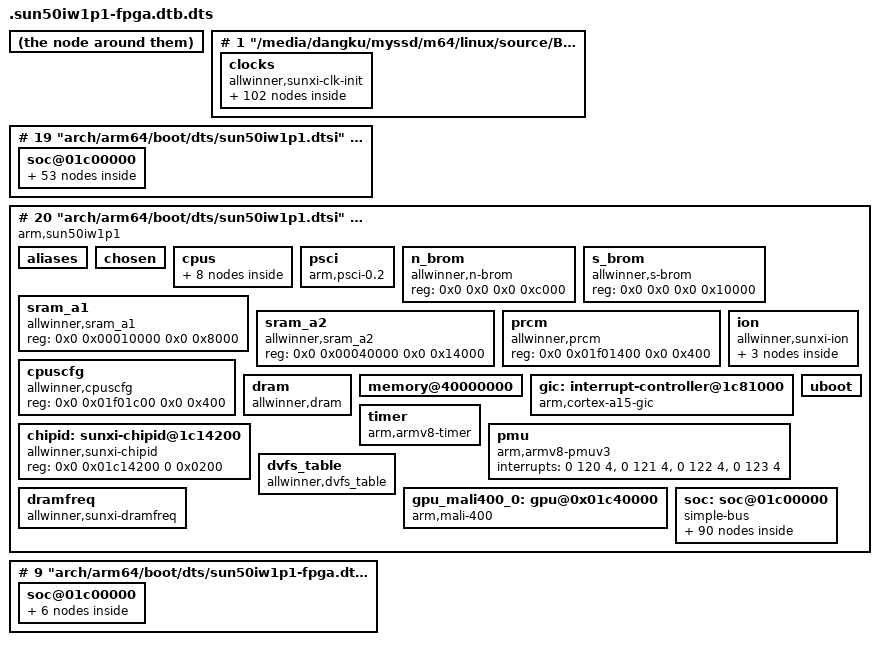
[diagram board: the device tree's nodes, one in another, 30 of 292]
# 1 "arch/arm64/boot/dts/sun50iw1p1-fpga.dts"
# 1 "<built-in>"
# 1 "<command-line>"
# 1 "arch/arm64/boot/dts/sun50iw1p1-fpga.dts"






/dts-v1/;
# 1 "arch/arm64/boot/dts/sun50iw1p1.dtsi" 1







/memreserve/ 0x45000000 0x00200000;
/memreserve/ 0x41010000 0x00010000;
/memreserve/ 0x41020000 0x00000800;

/memreserve/ 0x40100000 0x00004000;
/memreserve/ 0x40104000 0x00001000;
/memreserve/ 0x40105000 0x00001000;

# 1 "/media/dangku/myssd/m64/linux/source/BPI-M64-bsp-open/linux-sunxi/include/dt-bindings/interrupt-controller/arm-gic.h" 1







# 1 "/media/dangku/myssd/m64/linux/source/BPI-M64-bsp-open/linux-sunxi/include/dt-bindings/interrupt-controller/irq.h" 1
# 9 "/media/dangku/myssd/m64/linux/source/BPI-M64-bsp-open/linux-sunxi/include/dt-bindings/interrupt-controller/arm-gic.h" 2
# 17 "arch/arm64/boot/dts/sun50iw1p1.dtsi" 2
# 1 "/media/dangku/myssd/m64/linux/source/BPI-M64-bsp-open/linux-sunxi/include/dt-bindings/gpio/gpio.h" 1
# 18 "arch/arm64/boot/dts/sun50iw1p1.dtsi" 2
# 1 "arch/arm64/boot/dts/sun50iw1p1-clk.dtsi" 1
/{
clocks {
 compatible = "allwinner,sunxi-clk-init";
 device_type = "clocks";
 #address-cells = <2>;
 #size-cells = <2>;
 ranges;
 reg = <0x0 0x01c20000 0x0 0x0320> ,
    <0x0 0x01f01400 0x0 0x00B0> ,
    <0x0 0x01f00060 0x0 0x4>;

  clk_losc: losc {
   #clock-cells = <0>;
   compatible = "allwinner,fixed-clock";
   clock-frequency = <32768>;
   clock-output-names = "losc";
  };

  clk_iosc: iosc {
   #clock-cells = <0>;
   compatible = "allwinner,fixed-clock";
   clock-frequency = <16000000>;
   clock-output-names = "iosc";
  };

  clk_hosc: hosc {
   #clock-cells = <0>;
   compatible = "allwinner,fixed-clock";
   clock-frequency = <24000000>;
   clock-output-names = "hosc";
  };

  clk_pll_cpu: pll_cpu {
   #clock-cells = <0>;
   compatible = "allwinner,sunxi-pll-clock";
   lock-mode = "new";
   clock-output-names = "pll_cpu";
  };
  clk_pll_audio: pll_audio {
   #clock-cells = <0>;
   compatible = "allwinner,sunxi-pll-clock";
   lock-mode = "new";
   assigned-clock-rates = <24576000>;
   clock-output-names = "pll_audio";
  };
  clk_pll_video0: pll_video0 {
   #clock-cells = <0>;
   compatible = "allwinner,sunxi-pll-clock";
   lock-mode = "new";
   assigned-clock-rates = <297000000>;
   clock-output-names = "pll_video0";
  };
  clk_pll_ve: pll_ve {
   #clock-cells = <0>;
   compatible = "allwinner,sunxi-pll-clock";
   lock-mode = "new";
   clock-output-names = "pll_ve";
  };
  clk_pll_ddr0: pll_ddr0 {
   #clock-cells = <0>;
   compatible = "allwinner,sunxi-pll-clock";
   lock-mode = "new";
   clock-output-names = "pll_ddr0";
  };
  clk_pll_periph0: pll_periph0 {
   #clock-cells = <0>;
   compatible = "allwinner,sunxi-pll-clock";
   lock-mode = "new";
   clock-output-names = "pll_periph0";
  };
  clk_pll_periph1: pll_periph1 {
   #clock-cells = <0>;
   compatible = "allwinner,sunxi-pll-clock";
   lock-mode = "new";
   clock-output-names = "pll_periph1";
  };
  clk_pll_video1: pll_video1 {
   #clock-cells = <0>;
   compatible = "allwinner,sunxi-pll-clock";
   lock-mode = "new";
   assigned-clock-rates = <297000000>;
   clock-output-names = "pll_video1";
  };
  clk_pll_gpu: pll_gpu {
   #clock-cells = <0>;
   compatible = "allwinner,sunxi-pll-clock";
   lock-mode = "new";
   clock-output-names = "pll_gpu";
  };
  clk_pll_mipi: pll_mipi {
   #clock-cells = <0>;
   compatible = "allwinner,sunxi-pll-clock";
   lock-mode = "new";
   clock-output-names = "pll_mipi";
  };
  clk_pll_hsic: pll_hsic {
   #clock-cells = <0>;
   compatible = "allwinner,sunxi-pll-clock";
   lock-mode = "new";
   clock-output-names = "pll_hsic";
  };
  clk_pll_de: pll_de {
   #clock-cells = <0>;
   compatible = "allwinner,sunxi-pll-clock";
   lock-mode = "new";
   assigned-clock-rates = <297000000>;
   clock-output-names = "pll_de";
  };
  clk_pll_ddr1: pll_ddr1 {
   #clock-cells = <0>;
   compatible = "allwinner,sunxi-pll-clock";
   lock-mode = "new";
   clock-output-names = "pll_ddr1";
  };

  clk_pll_audiox8: pll_audiox8 {
   #clock-cells = <0>;
   compatible = "allwinner,fixed-factor-clock";
   clocks = <&clk_pll_audio>;
   clock-mult = <8>;
   clock-div = <1>;
   clock-output-names = "pll_audiox8";
  };
  clk_pll_audiox4: pll_audiox4 {
   #clock-cells = <0>;
   compatible = "allwinner,fixed-factor-clock";
   clocks = <&clk_pll_audio>;
   clock-mult = <8>;
   clock-div = <2>;
   clock-output-names = "pll_audiox4";
  };
  clk_pll_audiox2: pll_audiox2 {
   #clock-cells = <0>;
   compatible = "allwinner,fixed-factor-clock";
   clocks = <&clk_pll_audio>;
   clock-mult = <8>;
   clock-div = <4>;
   clock-output-names = "pll_audiox2";
  };
  clk_pll_video0x2: pll_video0x2 {
   #clock-cells = <0>;
   compatible = "allwinner,fixed-factor-clock";
   clocks = <&clk_pll_video0>;
   clock-mult = <2>;
   clock-div = <1>;
   clock-output-names = "pll_video0x2";
  };
  clk_pll_periph0x2: pll_periph0x2 {
   #clock-cells = <0>;
   compatible = "allwinner,fixed-factor-clock";
   clocks = <&clk_pll_periph0>;
   clock-mult = <2>;
   clock-div = <1>;
   clock-output-names = "pll_periph0x2";
  };
  clk_pll_periph1x2: pll_periph1x2 {
   #clock-cells = <0>;
   compatible = "allwinner,fixed-factor-clock";
   clocks = <&clk_pll_periph1>;
   clock-mult = <2>;
   clock-div = <1>;
   clock-output-names = "pll_periph1x2";
  };
  clk_pll_periph0d2: pll_periph0d2 {
   #clock-cells = <0>;
   compatible = "allwinner,fixed-factor-clock";
   clocks = <&clk_pll_periph0>;
   clock-mult = <1>;
   clock-div = <2>;
   clock-output-names = "pll_periph0d2";
  };
  clk_hoscd2: hoscd2 {
   #clock-cells = <0>;
   compatible = "allwinner,fixed-factor-clock";
   clocks = <&clk_hosc>;
   clock-mult = <1>;
   clock-div = <2>;
   clock-output-names = "hoscd2";
  };

  clk_cpu: cpu {
   #clock-cells = <0>;
   compatible = "allwinner,sunxi-periph-clock";
   clock-output-names = "cpu";
  };
  clk_cpuapb: cpuapb {
   #clock-cells = <0>;
   compatible = "allwinner,sunxi-periph-clock";
   clock-output-names = "cpuapb";
  };
  clk_axi: axi {
   #clock-cells = <0>;
   compatible = "allwinner,sunxi-periph-clock";
   clock-output-names = "axi";
  };
  clk_pll_periphahb0: pll_periphahb0 {
   #clock-cells = <0>;
   compatible = "allwinner,sunxi-periph-clock";
   clock-output-names = "pll_periphahb0";
  };
  clk_ahb1: ahb1 {
   #clock-cells = <0>;
   compatible = "allwinner,sunxi-periph-clock";
   clock-output-names = "ahb1";
  };
  clk_apb1: apb1 {
   #clock-cells = <0>;
   compatible = "allwinner,sunxi-periph-clock";
   clock-output-names = "apb1";
  };
  clk_apb2: apb2 {
   #clock-cells = <0>;
   compatible = "allwinner,sunxi-periph-clock";
   clock-output-names = "apb2";
  };
  clk_ahb2: ahb2 {
   #clock-cells = <0>;
   compatible = "allwinner,sunxi-periph-clock";
   clock-output-names = "ahb2";
  };
  clk_ths: ths {
   #clock-cells = <0>;
   compatible = "allwinner,sunxi-periph-clock";
   clock-output-names = "ths";
  };
  clk_nand: nand {
   #clock-cells = <0>;
   compatible = "allwinner,sunxi-periph-clock";
   clock-output-names = "nand";
  };
  clk_sdmmc0_mod: sdmmc0_mod {
   #clock-cells = <0>;
   compatible = "allwinner,sunxi-periph-clock";
   clock-output-names = "sdmmc0_mod";
  };
  clk_sdmmc0_bus: sdmmc0_bus {
   #clock-cells = <0>;
   compatible = "allwinner,sunxi-periph-clock";
   clock-output-names = "sdmmc0_bus";
  };
  clk_sdmmc0_rst: sdmmc0_rst {
   #clock-cells = <0>;
   compatible = "allwinner,sunxi-periph-clock";
   clock-output-names = "sdmmc0_rst";
  };

  clk_sdmmc1_mod: sdmmc1_mod {
   #clock-cells = <0>;
   compatible = "allwinner,sunxi-periph-clock";
   clock-output-names = "sdmmc1_mod";
  };
  clk_sdmmc1_bus: sdmmc1_bus {
   #clock-cells = <0>;
   compatible = "allwinner,sunxi-periph-clock";
   clock-output-names = "sdmmc1_bus";
  };
  clk_sdmmc1_rst: sdmmc1_rst {
   #clock-cells = <0>;
   compatible = "allwinner,sunxi-periph-clock";
   clock-output-names = "sdmmc1_rst";
  };
  clk_sdmmc2_mod: sdmmc2_mod {
   #clock-cells = <0>;
   compatible = "allwinner,sunxi-periph-clock";
   clock-output-names = "sdmmc2_mod";
  };
  clk_sdmmc2_bus: sdmmc2_bus {
   #clock-cells = <0>;
   compatible = "allwinner,sunxi-periph-clock";
   clock-output-names = "sdmmc2_bus";
  };
  clk_sdmmc2_rst: sdmmc2_rst {
   #clock-cells = <0>;
   compatible = "allwinner,sunxi-periph-clock";
   clock-output-names = "sdmmc2_rst";
  };
  clk_ts: ts {
   #clock-cells = <0>;
   compatible = "allwinner,sunxi-periph-clock";
   clock-output-names = "ts";
  };
  clk_ce: ce {
   #clock-cells = <0>;
   compatible = "allwinner,sunxi-periph-clock";
   clock-output-names = "ce";
  };
  clk_spi0: spi0 {
   #clock-cells = <0>;
   compatible = "allwinner,sunxi-periph-clock";
   clock-output-names = "spi0";
  };
  clk_spi1: spi1 {
   #clock-cells = <0>;
   compatible = "allwinner,sunxi-periph-clock";
   clock-output-names = "spi1";
  };
  clk_i2s0: i2s0 {
   #clock-cells = <0>;
   compatible = "allwinner,sunxi-periph-clock";
   clock-output-names = "i2s0";
  };
  clk_i2s1: i2s1 {
   #clock-cells = <0>;
   compatible = "allwinner,sunxi-periph-clock";
   clock-output-names = "i2s1";
  };
  clk_i2s2: i2s2 {
   #clock-cells = <0>;
   compatible = "allwinner,sunxi-periph-clock";
   clock-output-names = "i2s2";
  };
  clk_spdif: spdif {
   #clock-cells = <0>;
   compatible = "allwinner,sunxi-periph-clock";
   clock-output-names = "spdif";
  };
  clk_usbphy0: usbphy0 {
   #clock-cells = <0>;
   compatible = "allwinner,sunxi-periph-clock";
   clock-output-names = "usbphy0";
  };
  clk_usbphy1: usbphy1 {
   #clock-cells = <0>;
   compatible = "allwinner,sunxi-periph-clock";
   clock-output-names = "usbphy1";
  };
  clk_usbhsic: usbhsic {
   #clock-cells = <0>;
   compatible = "allwinner,sunxi-periph-clock";
   clock-output-names = "usbhsic";
  };
  clk_usbhsic12m: usbhsic12m {
   #clock-cells = <0>;
   compatible = "allwinner,sunxi-periph-clock";
   clock-output-names = "usbhsic12m";
  };
  clk_usbohci1: usbohci1 {
   #clock-cells = <0>;
   compatible = "allwinner,sunxi-periph-clock";
   clock-output-names = "usbohci1";
  };
  clk_usbohci0: usbohci0 {
   #clock-cells = <0>;
   compatible = "allwinner,sunxi-periph-clock";
   clock-output-names = "usbohci0";
  };
  clk_de: de {
   #clock-cells = <0>;
   compatible = "allwinner,sunxi-periph-clock";
   assigned-clock-parents = <&clk_pll_de>;
   assigned-clock-rates = <297000000>;
   clock-output-names = "de";
  };
  clk_tcon0: tcon0 {
   #clock-cells = <0>;
   compatible = "allwinner,sunxi-periph-clock";
   assigned-clock-parents = <&clk_pll_mipi>;
   clock-output-names = "tcon0";
  };
  clk_tcon1: tcon1 {
   #clock-cells = <0>;
   compatible = "allwinner,sunxi-periph-clock";
   assigned-clock-parents = <&clk_pll_video0>;
   clock-output-names = "tcon1";
  };
  clk_deinterlace: deinterlace {
   #clock-cells = <0>;
   compatible = "allwinner,sunxi-periph-clock";
   clock-output-names = "deinterlace";
  };
  clk_csi_s: csi_s {
   #clock-cells = <0>;
   compatible = "allwinner,sunxi-periph-clock";
   clock-output-names = "csi_s";
  };
  clk_csi_m: csi_m {
   #clock-cells = <0>;
   compatible = "allwinner,sunxi-periph-clock";
   clock-output-names = "csi_m";
  };
  clk_csi_misc: csi_misc {
   #clock-cells = <0>;
   compatible = "allwinner,sunxi-periph-clock";
   clock-output-names = "csi_misc";
  };
  clk_ve: ve {
   #clock-cells = <0>;
   compatible = "allwinner,sunxi-periph-clock";
   clock-output-names = "ve";
  };
  clk_adda: adda {
   #clock-cells = <0>;
   compatible = "allwinner,sunxi-periph-clock";
   clock-output-names = "adda";
  };
  clk_addax4: addax4 {
   #clock-cells = <0>;
   compatible = "allwinner,sunxi-periph-clock";
   clock-output-names = "addax4";
  };
  clk_avs: avs {
   #clock-cells = <0>;
   compatible = "allwinner,sunxi-periph-clock";
   clock-output-names = "avs";
  };
  clk_hdmi: hdmi {
   #clock-cells = <0>;
   compatible = "allwinner,sunxi-periph-clock";
   assigned-clock-parents = <&clk_pll_video0>;
   clock-output-names = "hdmi";
  };
  clk_hdmi_slow: hdmi_slow {
   #clock-cells = <0>;
   compatible = "allwinner,sunxi-periph-clock";
   clock-output-names = "hdmi_slow";
  };
  clk_mbus: mbus {
   #clock-cells = <0>;
   compatible = "allwinner,sunxi-periph-clock";
   clock-output-names = "mbus";
  };
  clk_mipidsi: mipidsi {
   #clock-cells = <0>;
   compatible = "allwinner,sunxi-periph-clock";
   clock-output-names = "mipidsi";
  };
  clk_gpu: gpu {
   #clock-cells = <0>;
   compatible = "allwinner,sunxi-periph-clock";
   clock-output-names = "gpu";
  };
  clk_usbohci_16: usbehci_16 {
   #clock-cells = <0>;
   compatible = "allwinner,sunxi-periph-clock";
   clock-output-names = "usbohci_16";
  };
  clk_usbehci1: usbehci1 {
   #clock-cells = <0>;
   compatible = "allwinner,sunxi-periph-clock";
   clock-output-names = "usbehci1";
  };
  clk_usbehci0: usbehci0 {
   #clock-cells = <0>;
   compatible = "allwinner,sunxi-periph-clock";
   clock-output-names = "usbehci0";
  };
  clk_usbotg: usbotg {
   #clock-cells = <0>;
   compatible = "allwinner,sunxi-periph-clock";
   clock-output-names = "usbotg";
  };
  clk_gmac: gmac {
   #clock-cells = <0>;
   compatible = "allwinner,sunxi-periph-clock";
   clock-output-names = "gmac";
  };
  clk_sdram: sdram {
   #clock-cells = <0>;
   compatible = "allwinner,sunxi-periph-clock";
   clock-output-names = "sdram";
  };
  clk_dma: dma {
   #clock-cells = <0>;
   compatible = "allwinner,sunxi-periph-clock";
   clock-output-names = "dma";
  };
  clk_hwspinlock_rst: hwspinlock_rst {
   #clock-cells = <0>;
   compatible = "allwinner,sunxi-periph-clock";
   clock-output-names = "hwspinlock_rst";
  };
  clk_hwspinlock_bus: hwspinlock_bus {
   #clock-cells = <0>;
   compatible = "allwinner,sunxi-periph-clock";
   clock-output-names = "hwspinlock_bus";
  };
  clk_msgbox: msgbox {
   #clock-cells = <0>;
   compatible = "allwinner,sunxi-periph-clock";
   clock-output-names = "msgbox";
  };
  clk_lvds: lvds {
   #clock-cells = <0>;
   compatible = "allwinner,sunxi-periph-clock";
   clock-output-names = "lvds";
  };
  clk_uart0: uart0 {
   #clock-cells = <0>;
   compatible = "allwinner,sunxi-periph-clock";
   clock-output-names = "uart0";
  };
  clk_uart1: uart1 {
   #clock-cells = <0>;
   compatible = "allwinner,sunxi-periph-clock";
   clock-output-names = "uart1";
  };
  clk_uart2: uart2 {
   #clock-cells = <0>;
   compatible = "allwinner,sunxi-periph-clock";
   clock-output-names = "uart2";
  };
  clk_uart3: uart3 {
   #clock-cells = <0>;
   compatible = "allwinner,sunxi-periph-clock";
   clock-output-names = "uart3";
  };
  clk_uart4: uart4 {
   #clock-cells = <0>;
   compatible = "allwinner,sunxi-periph-clock";
   clock-output-names = "uart4";
  };
  clk_scr: scr {
   #clock-cells = <0>;
   compatible = "allwinner,sunxi-periph-clock";
   clock-output-names = "scr";
  };
  clk_twi0: twi0 {
   #clock-cells = <0>;
   compatible = "allwinner,sunxi-periph-clock";
   clock-output-names = "twi0";
  };
  clk_twi1: twi1 {
   #clock-cells = <0>;
   compatible = "allwinner,sunxi-periph-clock";
   clock-output-names = "twi1";
  };
  clk_twi2: twi2 {
   #clock-cells = <0>;
   compatible = "allwinner,sunxi-periph-clock";
   clock-output-names = "twi2";
  };
  clk_twi3: twi3 {
   #clock-cells = <0>;
   compatible = "allwinner,sunxi-periph-clock";
   clock-output-names = "twi3";
  };
  clk_pio: pio {
   #clock-cells = <0>;
   compatible = "allwinner,sunxi-periph-clock";
   clock-output-names = "pio";
  };

  clk_cpurcir: cpurcir {
   #clock-cells = <0>;
   compatible = "allwinner,sunxi-periph-cpus-clock";
   clock-output-names = "cpurcir";
  };
  clk_cpurpio: cpurpio {
   #clock-cells = <0>;
   compatible = "allwinner,sunxi-periph-cpus-clock";
   clock-output-names = "cpurpio";
  };

  clk_cpurpll_peri0: cpurpll_peri0 {
   #clock-cells = <0>;
   compatible = "allwinner,sunxi-periph-cpus-clock";
   clock-output-names = "cpurpll_peri0";
  };
  clk_cpurcpus: cpurcpus {
   #clock-cells = <0>;
   compatible = "allwinner,sunxi-periph-cpus-clock";
   clock-output-names = "cpurcpus";
  };
  clk_cpurahbs: cpurahbs {
   #clock-cells = <0>;
   compatible = "allwinner,sunxi-periph-cpus-clock";
   clock-output-names = "cpurahbs";
  };
  clk_cpurapbs: cpurapbs {
   #clock-cells = <0>;
   compatible = "allwinner,sunxi-periph-cpus-clock";
   clock-output-names = "cpurapbs";
  };
  clk_losc_out: losc_out {
   #clock-cells = <0>;
   compatible = "allwinner,sunxi-periph-cpus-clock";
   clock-output-names = "losc_out";
  };
 };
};
# 19 "arch/arm64/boot/dts/sun50iw1p1.dtsi" 2
# 1 "arch/arm64/boot/dts/sun50iw1p1-pinctrl.dtsi" 1




/ {
 soc@01c00000{
  r_pio: pinctrl@01f02c00 {
   compatible = "allwinner,sun50i-r-pinctrl";
   reg = <0x0 0x01f02c00 0x0 0x400>;
   interrupts = <0 45 4>;
   clocks = <&clk_cpurpio>;
   device_type = "r_pio";

   gpio-controller;
   interrupt-controller;
   #interrupt-cells = <2>;
   #size-cells = <0>;
   #gpio-cells = <6>;

   s_uart0_pins_a: s_uart0@0 {
    allwinner,pins = "PL2", "PL3";
    allwinner,function = "s_uart0";
    allwinner,muxsel = <2>;
    allwinner,drive = <1>;
    allwinner,pull = <1>;
   };

   s_rsb0_pins_a: s_rsb0@0 {
    allwinner,pins = "PL0", "PL1";
    allwinner,function = "s_rsb0";
    allwinner,muxsel = <2>;
    allwinner,drive = <2>;
    allwinner,pull = <1>;
   };

   s_jtag0_pins_a: s_jtag0@0 {
    allwinner,pins = "PL4", "PL5", "PL6", "PL7";
    allwinner,function = "s_jtag0";
    allwinner,muxsel = <2>;
    allwinner,drive = <2>;
    allwinner,pull = <1>;
   };

   s_cir0_pins_a: s_cir0@0 {
    allwinner,pins = "PL11";
    allwinner,function = "s_cir0";
    allwinner,muxsel = <2>;
    allwinner,drive = <2>;
    allwinner,pull = <1>;
   };
  };

  pio: pinctrl@01c20800 {
   compatible = "allwinner,sun50i-pinctrl";
   reg = <0x0 0x01c20800 0x0 0x400>;
   interrupts = <0 11 4>,
         <0 17 4>,
         <0 21 4>;
   device_type = "pio";
   clocks = <&clk_pio>;
   gpio-controller;
   interrupt-controller;
   #interrupt-cells = <2>;
   #size-cells = <0>;
   #gpio-cells = <6>;

   vdevice_pins_a: vdevice@0 {
    allwinner,pins = "PB0", "PB1";
    allwinner,function = "vdevice";
    allwinner,muxsel = <3>;
    allwinner,drive = <1>;
    allwinner,pull = <1>;
   };

   uart0_pins_a: uart0@0 {
    allwinner,pins = "PB8", "PB9";
    allwinner,pname = "uart0_tx", "uart0_rx";
    allwinner,function = "uart0";
    allwinner,muxsel = <4>;
    allwinner,drive = <1>;
    allwinner,pull = <1>;
   };

   uart0_pins_b: uart0@1 {
    allwinner,pins = "PB8", "PB9";
    allwinner,function = "io_disabled";
    allwinner,muxsel = <7>;
    allwinner,drive = <1>;
    allwinner,pull = <1>;
   };

   uart1_pins_a: uart1@0 {
    allwinner,pins = "PG6", "PG7", "PG8", "PG9";
    allwinner,pname = "uart1_tx", "uart1_rx", "uart1_rts", "uart1_cts";
    allwinner,function = "uart1";
    allwinner,muxsel = <2>;
    allwinner,drive = <1>;
    allwinner,pull = <1>;
   };

   uart1_pins_b: uart1@1 {
    allwinner,pins = "PG6", "PG7", "PG8", "PG9";
    allwinner,function = "io_disabled";
    allwinner,muxsel = <7>;
    allwinner,drive = <1>;
    allwinner,pull = <1>;
   };

   uart2_pins_a: uart2@0 {
    allwinner,pins = "PB0", "PB1", "PB2", "PB3";
    allwinner,pname = "uart2_tx", "uart2_rx", "uart2_rts", "uart2_cts";
    allwinner,function = "uart2";
    allwinner,muxsel = <2>;
    allwinner,drive = <1>;
    allwinner,pull = <1>;
   };

   uart2_pins_b: uart2@1 {
    allwinner,pins = "PB0", "PB1", "PB2", "PB3";
    allwinner,function = "io_disabled";
    allwinner,muxsel = <7>;
    allwinner,drive = <1>;
    allwinner,pull = <1>;
   };

   uart3_pins_a: uart3@0 {
    allwinner,pins = "PH4", "PH5", "PH6", "PH7";
    allwinner,pname = "uart3_tx", "uart3_rx", "uart3_rts", "uart3_cts";
    allwinner,function = "uart3";
    allwinner,muxsel = <2>;
    allwinner,drive = <1>;
    allwinner,pull = <1>;
   };

   uart3_pins_b: uart3@1 {
    allwinner,pins = "PH4", "PH5", "PH6", "PH7";
    allwinner,function = "io_disabled";
    allwinner,muxsel = <7>;
    allwinner,drive = <1>;
    allwinner,pull = <1>;
   };

   uart4_pins_a: uart4@0 {
    allwinner,pins = "PD2", "PD3", "PD4", "PD5";
    allwinner,pname = "uart4_tx", "uart4_rx", "uart4_rts", "uart4_cts";
    allwinner,function = "uart4";
    allwinner,muxsel = <3>;
    allwinner,drive = <1>;
    allwinner,pull = <1>;
   };

   uart4_pins_b: uart4@1 {
    allwinner,pins = "PD2", "PD3", "PD4", "PD5";
    allwinner,function = "io_disabled";
    allwinner,muxsel = <7>;
    allwinner,drive = <1>;
    allwinner,pull = <1>;
   };

   twi0_pins_a: twi0@0 {
    allwinner,pins = "PH0", "PH1";
    allwinner,pname = "twi0_scl", "twi0_sda";
    allwinner,function = "twi0";
    allwinner,muxsel = <2>;
    allwinner,drive = <1>;
    allwinner,pull = <0>;
   };

   twi0_pins_b: twi0@1 {
    allwinner,pins = "PH0", "PH1";
    allwinner,function = "io_disabled";
    allwinner,muxsel = <7>;
    allwinner,drive = <1>;
    allwinner,pull = <0>;
   };

   twi1_pins_a: twi1@0 {
    allwinner,pins = "PH2", "PH3";
    allwinner,pname = "twi1_scl", "twi1_sda";
    allwinner,function = "twi1";
    allwinner,muxsel = <2>;
    allwinner,drive = <1>;
    allwinner,pull = <0>;
   };

   twi1_pins_b: twi1@1 {
    allwinner,pins = "PH2", "PH3";
    allwinner,function = "io_disabled";
    allwinner,muxsel = <7>;
    allwinner,drive = <1>;
    allwinner,pull = <0>;
   };

   twi2_pins_a: twi2@0 {
    allwinner,pins = "PE14", "PE15";
    allwinner,pname = "twi2_scl", "twi2_sda";
    allwinner,function = "twi2";
    allwinner,muxsel = <3>;
    allwinner,drive = <1>;
    allwinner,pull = <0>;
   };

   twi2_pins_b: twi2@1 {
    allwinner,pins = "PE14", "PE15";
    allwinner,function = "io_disabled";
    allwinner,muxsel = <7>;
    allwinner,drive = <1>;
    allwinner,pull = <0>;
   };

   spi0_pins_a: spi0@0 {
    allwinner,pins = "PC2", "PC0", "PC1";
    allwinner,pname = "spi0_sclk", "spi0_mosi", "spi0_miso";
    allwinner,function = "spi0";
    allwinner,muxsel = <4>;
    allwinner,drive = <1>;
    allwinner,pull = <0>;
   };

   spi0_pins_b: spi0@1 {
    allwinner,pins = "PC3";
    allwinner,pname = "spi0_cs0";
    allwinner,function = "spi0";
    allwinner,muxsel = <4>;
    allwinner,drive = <1>;
    allwinner,pull = <1>;
   };

   spi0_pins_c: spi0@2 {
    allwinner,pins = "PC3", "PC2", "PC0", "PC1";
    allwinner,function = "io_disabled";
    allwinner,muxsel = <7>;
    allwinner,drive = <1>;
    allwinner,pull = <0>;
   };

   spi1_pins_a: spi1@0 {
    allwinner,pins = "PD1", "PD2", "PD3";
    allwinner,pname = "spi1_sclk", "spi1_mosi", "spi1_miso";
    allwinner,function = "spi1";
    allwinner,muxsel = <4>;
    allwinner,drive = <1>;
    allwinner,pull = <0>;
   };

   spi1_pins_b: spi1@1 {
    allwinner,pins = "PD0";
    allwinner,pname = "spi1_cs0";
    allwinner,function = "spi1";
    allwinner,muxsel = <4>;
    allwinner,drive = <1>;
    allwinner,pull = <1>;
   };

   spi1_pins_c: spi1@2 {
    allwinner,pins = "PD0", "PD1", "PD2", "PD3";
    allwinner,function = "io_disabled";
    allwinner,muxsel = <7>;
    allwinner,drive = <1>;
    allwinner,pull = <0>;
   };

   sdc0_pins_a: sdc0@0 {
    allwinner,pins = "PF0", "PF1", "PF2", "PF3","PF4","PF5";
    allwinner,function = "sdc0";
    allwinner,muxsel = <2>;
    allwinner,drive = <1>;
    allwinner,pull = <1>;
   };

   sdc0_pins_b: sdc0@1 {
    allwinner,pins = "PF0", "PF1", "PF2", "PF3","PF4","PF5";
    allwinner,function = "io_disabled";
    allwinner,muxsel = <7>;
    allwinner,drive = <1>;
    allwinner,pull = <1>;
   };

   sdc1_pins_a: sdc1@0 {
    allwinner,pins = "PG0", "PG1", "PG2", "PG3","PG4","PG5";
    allwinner,function = "sdc1";
    allwinner,muxsel = <2>;
    allwinner,drive = <3>;
    allwinner,pull = <1>;
   };

   sdc1_pins_b: sdc1@1 {
    allwinner,pins = "PG0", "PG1", "PG2", "PG3","PG4","PG5";
    allwinner,function = "io_disabled";
    allwinner,muxsel = <7>;
    allwinner,drive = <1>;
    allwinner,pull = <1>;
   };

   sdc2_pins_a: sdc2@0 {
    allwinner,pins = "PC1","PC5", "PC6", "PC8", "PC9","PC10","PC11","PC12","PC13","PC14","PC15","PC16";
    allwinner,function = "sdc2";
    allwinner,muxsel = <3>;
    allwinner,drive = <2>;
    allwinner,pull = <1>;
   };

   sdc2_pins_b: sdc2@1 {
   allwinner,pins = "PC1","PC5", "PC6", "PC8", "PC9","PC10","PC11","PC12","PC13","PC14","PC15","PC16";
    allwinner,function = "io_disabled";
    allwinner,muxsel = <7>;
    allwinner,drive = <1>;
    allwinner,pull = <1>;
   };

   daudio0_pins_a: daudio0@0 {
    allwinner,pins = "PB6", "PB3", "PB4", "PB5", "PB7";
    allwinner,function = "pcm0";
    allwinner,muxsel = <3>;
    allwinner,drive = <1>;
    allwinner,pull = <0>;
   };
   daudio0_pins_b: daudio0_sleep@0 {
    allwinner,pins = "PB6", "PB3", "PB4", "PB5", "PB7";
    allwinner,function = "io_disabled";
    allwinner,muxsel = <7>;
    allwinner,drive = <1>;
    allwinner,pull = <0>;
   };
   daudio1_pins_a: daudio1@0 {
    allwinner,pins = "PG10", "PG11", "PG12", "PG13";
    allwinner,function = "pcm1";
    allwinner,muxsel = <3>;
    allwinner,drive = <1>;
    allwinner,pull = <0>;
   };
   daudio1_pins_b: daudio1_sleep@0 {
    allwinner,pins = "PG10", "PG11", "PG12", "PG13";
    allwinner,function = "io_disabled";
    allwinner,muxsel = <7>;
    allwinner,drive = <1>;
    allwinner,pull = <0>;
   };
   aif2_pins_a: aif2@0 {
    allwinner,pins = "PB6", "PB4", "PB5", "PB7";
    allwinner,function = "aif2";
    allwinner,muxsel = <2>;
    allwinner,drive = <1>;
    allwinner,pull = <0>;
   };
   aif3_pins_a: aif3@0 {
    allwinner,pins = "PG10", "PG11", "PG12", "PG13";
    allwinner,function = "aif3";
    allwinner,muxsel = <2>;
    allwinner,drive = <1>;
    allwinner,pull = <0>;
   };
   aif2_pins_b: aif2_sleep@0 {
    allwinner,pins = "PB6", "PB4", "PB5", "PB7";
    allwinner,function = "io_disabled";
    allwinner,muxsel = <7>;
    allwinner,drive = <1>;
    allwinner,pull = <0>;
   };
   aif3_pins_b: aif3_sleep@0 {
    allwinner,pins = "PG10", "PG11", "PG12", "PG13";
    allwinner,function = "io_disabled";
    allwinner,muxsel = <7>;
    allwinner,drive = <1>;
    allwinner,pull = <0>;
   };
   spdif_pins_a: spdif@0 {
    allwinner,pins = "PH8";
    allwinner,function = "spdif0";
    allwinner,muxsel = <2>;
    allwinner,drive = <1>;
    allwinner,pull = <0>;
   };
   spdif_pins_b: spdif_sleep@0 {
    allwinner,pins = "PH8";
    allwinner,function = "io_disabled";
    allwinner,muxsel = <7>;
    allwinner,drive = <1>;
    allwinner,pull = <0>;
   };

   csi0_pins_a: csi0@0 {
    allwinner,pins = "PE0","PE2","PE3","PE4","PE5","PE6","PE7","PE8","PE9","PE10","PE11","PE12","PE13";
    allwinner,pname = "csi0_pck","csi0_hsync","csi0_vsync","csi0_d0","csi0_d1","csi0_d2",
        "csi0_d3","csi0_d4","csi0_d5","csi0_d6","csi0_d7","csi0_sck","csi0_sda";
    allwinner,function = "csi0";
    allwinner,muxsel = <2>;
    allwinner,drive = <1>;
    allwinner,pull = <0>;
    allwinner,data = <0>;
   };
   csi0_pins_b: csi0_sleep@0 {
    allwinner,pins = "PE0","PE2","PE3","PE4","PE5","PE6","PE7","PE8","PE9","PE10","PE11","PE12","PE13";
    allwinner,pname = "csi0_pck","csi0_hsync","csi0_vsync","csi0_d0","csi0_d1","csi0_d2",
        "csi0_d3","csi0_d4","csi0_d5","csi0_d6","csi0_d7","csi0_sck","csi0_sda";
    allwinner,function = "io_disabled";
    allwinner,muxsel = <7>;
    allwinner,drive = <1>;
    allwinner,pull = <0>;
    allwinner,data = <0>;
   };

   scr_pins_a: smartcard@0 {
    allwinner,pins = "PB1", "PB4", "PB5", "PB6","PB7";
    allwinner,function = "sim0";
    allwinner,muxsel = <5>;
    allwinner,drive = <1>;
    allwinner,pull = <1>;
   };

   nand0_pins_a: nand0@0 {
    allwinner,pins ="PC0", "PC1", "PC2", "PC5", "PC8", "PC9", "PC10", "PC11", "PC12", "PC13","PC14", "PC15","PC16";
    allwinner,pname= "nand0_we", "nand0_ale", "nand0_cle", "nand0_nre", "nand0_d0", "nand0_d1", "nand0_d2", "nand0_d3", "nand0_d4", "nand0_d5", "nand0_d6", "nand0_d7", "nand0_ndqs";
    allwinner,function = "nand0";
    allwinner,muxsel = <2>;
    allwinner,drive = <1>;
    allwinner,pull = <0>;
   };

   nand0_pins_b: nand0@1 {
    allwinner,pins ="PC3", "PC4", "PC6", "PC7", "PC17","PC18";
    allwinner,pname= "nand0_ce1", "nand0_ce0", "nand0_rb0", "nand0_rb1", "nand0_ce2", "nand0_ce3";
    allwinner,function = "nand0";
    allwinner,muxsel = <2>;
    allwinner,drive = <1>;
    allwinner,pull = <1>;
   };

   nand0_pins_c: nand0@2 {
    allwinner,pins ="PC0", "PC1", "PC2", "PC3", "PC4", "PC5", "PC6", "PC7", "PC8", "PC9", "PC10", "PC11", "PC12", "PC13", "PC14", "PC15", "PC16", "PC17", "PC18";
    allwinner,function = "io_disabled";
    allwinner,muxsel = <7>;
    allwinner,drive = <1>;
    allwinner,pull = <0>;
   };

   gmac_pins_a: gmac@0 {
    allwinner,pins = "PD8", "PD9", "PD10", "PD11",
      "PD12", "PD13", "PD14", "PD15",
      "PD16", "PD17", "PD18", "PD19",
      "PD20", "PD21", "PD22", "PD23";
    allwinner,function = "gmac0";
    allwinner,muxsel = <4>;
    allwinner,drive = <3>;
    allwinner,pull = <0>;
   };
  };

  axp_pio: pinctrl@0 {
   compatible = "allwinner,axp-pinctrl";
   gpio-controller;
   #size-cells = <0>;
   #gpio-cells = <6>;
   device_type = "axp_pio";
  };
 };
};
# 20 "arch/arm64/boot/dts/sun50iw1p1.dtsi" 2
/ {
 model = "sun50iw1p1";
 compatible = "arm,sun50iw1p1", "arm,sun50iw1p1";
 interrupt-parent = <&gic>;
 #address-cells = <2>;
 #size-cells = <2>;

 aliases {
  serial0 = &uart0;
  serial1 = &uart1;
  serial2 = &uart2;
  serial3 = &uart3;
  serial4 = &uart4;
  twi0 = &twi0;
  twi1 = &twi1;
  twi2 = &twi2;
  spi0 = &spi0;
  spi1 = &spi1;
  global_timer0 = &soc_timer0;
  cci0 = &csi_cci0;
  csi_res0 = &csi_res0;
  vfe0 = &csi0;
  mmc0 = &sdc0;
  mmc2 = &sdc2;
  nand0 =&nand0;
  disp = &disp;
  lcd0 = &lcd0;
  hdmi = &hdmi;
  pwm = &pwm;
  pwm0 = &pwm0;
  s_pwm = &s_pwm;
  spwm0 = &spwm0;
  boot_disp = &boot_disp;
 };

 chosen {
  bootargs = "earlyprintk=sunxi-uart,0x01c28000 loglevel=8 initcall_debug=1 console=ttyS0 init=/init";
  linux,initrd-start = <0x0 0x0>;
  linux,initrd-end = <0x0 0x0>;
 };

 cpus {
  #address-cells = <2>;
  #size-cells = <0>;

  cpu@0 {
   device_type = "cpu";
   compatible = "arm,cortex-a53","arm,armv8";
   reg = <0x0 0x0>;
   enable-method = "psci";
   cpufreq_tbl = < 480000
     600000
     720000
     816000
     912000
     960000
     1008000
     1056000
     1104000
     1152000
     1200000
     1344000>;
   clock-latency = <2000000>;
   clock-frequency = <1008000000>;
   cpu-idle-states = <&CPU_SLEEP_0 &CLUSTER_SLEEP_0 &SYS_SLEEP_0>;
  };
  cpu@1 {
   device_type = "cpu";
   compatible = "arm,cortex-a53","arm,armv8";
   reg = <0x0 0x1>;
   enable-method = "psci";
   clock-frequency = <1008000000>;
   cpu-idle-states = <&CPU_SLEEP_0 &CLUSTER_SLEEP_0 &SYS_SLEEP_0>;
  };
  cpu@2 {
   device_type = "cpu";
   compatible = "arm,cortex-a53","arm,armv8";
   reg = <0x0 0x2>;
   enable-method = "psci";
   clock-frequency = <1008000000>;
   cpu-idle-states = <&CPU_SLEEP_0 &CLUSTER_SLEEP_0 &SYS_SLEEP_0>;
  };
  cpu@3 {
   device_type = "cpu";
   compatible = "arm,cortex-a53","arm,armv8";
   reg = <0x0 0x3>;
   enable-method = "psci";
   clock-frequency = <1008000000>;
   cpu-idle-states = <&CPU_SLEEP_0 &CLUSTER_SLEEP_0 &SYS_SLEEP_0>;
  };
  idle-states {
   entry-method = "arm,psci";

   CPU_SLEEP_0: cpu-sleep-0 {
    compatible = "arm,idle-state";
    arm,psci-suspend-param = <0x0010000>;
    entry-latency-us = <40>;
    exit-latency-us = <100>;
    min-residency-us = <150>;
   };

   CLUSTER_SLEEP_0: cluster-sleep-0 {
    compatible = "arm,idle-state";
    arm,psci-suspend-param = <0x1010000>;
    entry-latency-us = <500>;
    exit-latency-us = <1000>;
    min-residency-us = <2500>;
   };

   SYS_SLEEP_0: sys-sleep-0 {
    compatible = "arm,idle-state";
    arm,psci-suspend-param = <0x2010000>;
    entry-latency-us = <1000>;
    exit-latency-us = <2000>;
    min-residency-us = <4500>;
   };
  };
 };

 psci {
     compatible = "arm,psci-0.2";
     method = "smc";
     psci_version = <0x84000000>;
     cpu_suspend = <0xc4000001>;
     cpu_off = <0x84000002>;
     cpu_on = <0xc4000003>;
     affinity_info = <0xc4000004>;
     migrate = <0xc4000005>;
     migrate_info_type = <0x84000006>;
     migrate_info_up_cpu = <0xc4000007>;
     system_off = <0x84000008>;
     system_reset = <0x84000009>;

 };
 n_brom {
  compatible = "allwinner,n-brom";
  reg = <0x0 0x0 0x0 0xc000>;
 };

 s_brom {
  compatible = "allwinner,s-brom";
  reg = <0x0 0x0 0x0 0x10000>;
 };

 sram_a1 {
  compatible = "allwinner,sram_a1";
  reg = <0x0 0x00010000 0x0 0x8000>;
 };

 sram_a2 {
  compatible = "allwinner,sram_a2";
  reg = <0x0 0x00040000 0x0 0x14000>;
 };

 prcm {
  compatible = "allwinner,prcm";
  reg = <0x0 0x01f01400 0x0 0x400>;
 };

 cpuscfg {
  compatible = "allwinner,cpuscfg";
  reg = <0x0 0x01f01c00 0x0 0x400>;
 };

 ion {
  compatible = "allwinner,sunxi-ion";







  system_contig{
   type = <1>;
   name = "system_contig";
  };
  cma{
   type = <4>;
   name = "cma";
  };
  system{
   type = <0>;
   name = "system";
  };
 };

 dram: dram {
  compatible = "allwinner,dram";
  clocks = <&clk_pll_ddr0>, <&clk_pll_ddr1>;
  clock-names = "pll_ddr0", "pll_ddr1";
  dram_clk = <672>;
  dram_type = <3>;
  dram_zq = <0x003F3FDD>;
  dram_odt_en = <1>;
  dram_para1 = <0x10f41000>;
  dram_para2 = <0x00001200>;
  dram_mr0 = <0x1A50>;
  dram_mr1 = <0x40>;
  dram_mr2 = <0x10>;
  dram_mr3 = <0>;
  dram_tpr0 = <0x04E214EA>;
  dram_tpr1 = <0x004214AD>;
  dram_tpr2 = <0x10A75030>;
  dram_tpr3 = <0>;
  dram_tpr4 = <0>;
  dram_tpr5 = <0>;
  dram_tpr6 = <0>;
  dram_tpr7 = <0>;
  dram_tpr8 = <0>;
  dram_tpr9 = <0>;
  dram_tpr10 = <0>;
  dram_tpr11 = <0>;
  dram_tpr12 = <168>;
  dram_tpr13 = <0x823>;
 };

 memory@40000000 {
  device_type = "memory";
  reg = <0x00000000 0x40000000 0x00000000 0x40000000>;
 };

 gic: interrupt-controller@1c81000 {
  compatible = "arm,cortex-a15-gic", "arm,cortex-a9-gic";
  #interrupt-cells = <3>;
  #address-cells = <0>;
  device_type = "gic";
  interrupt-controller;
  reg = <0x0 0x01c81000 0 0x1000>,
        <0x0 0x01c82000 0 0x2000>,
        <0x0 0x01c84000 0 0x2000>,
        <0x0 0x01c86000 0 0x2000>;
  interrupts = <1 9 0xf04>;
 };

 chipid: sunxi-chipid@1c14200 {
  compatible = "allwinner,sunxi-chipid";
  device_type = "chipid";
  reg = <0x0 0x01c14200 0 0x0200>;
 };

 timer {
  compatible = "arm,armv8-timer";
  interrupts = <1 13 0xff01>,
        <1 14 0xff01>,
        <1 11 0xff01>,
        <1 10 0xff01>;
  clock-frequency = <24000000>;
 };

 pmu {
  compatible = "arm,armv8-pmuv3";
  interrupts = <0 120 4>,
        <0 121 4>,
        <0 122 4>,
        <0 123 4>;
 };

 dvfs_table: dvfs_table {
  compatible = "allwinner,dvfs_table";
  max_freq = <1152000000>;
  min_freq = <480000000>;
  lv_count = <8>;
  lv1_freq = <1152000000>;
  lv1_volt = <1300>;
  lv2_freq = <1104000000>;
  lv2_volt = <1260>;
  lv3_freq = <1056000000>;
  lv3_volt = <1240>;
  lv4_freq = <1008000000>;
  lv4_volt = <1200>;
  lv5_freq = <960000000>;
  lv5_volt = <1160>;
  lv6_freq = <912000000>;
  lv6_volt = <1120>;
  lv7_freq = <816000000>;
  lv7_volt = <1080>;
  lv8_freq = <648000000>;
  lv8_volt = <1040>;
 };

 dramfreq {
  compatible = "allwinner,sunxi-dramfreq";
  reg = <0x0 0x01c62000 0x0 0x1000>,
    <0x0 0x01c63000 0x0 0x1000>,
    <0x0 0x01c20000 0x0 0x800>;
  clocks = <&clk_pll_ddr0>,<&clk_pll_ddr1>,<&clk_ahb1>;
  status = "okay";
 };

 uboot: uboot {
 };

 gpu_mali400_0: gpu@0x01c40000 {
  compatible = "arm,mali-400", "arm,mali-utgard";
  reg = <0x0 0x01c40000 0x0 0x10000>;
  interrupts = <0 97 4>, <0 98 4>, <0 99 4>, <0 100 4>, <0 102 4>, <0 103 4>;
  interrupt-names = "IRQGP", "IRQGPMMU", "IRQPP0", "IRQPPMMU0", "IRQPP1", "IRQPPMMU1";
  clocks = <&clk_pll_gpu>, <&clk_gpu>;
 };

 soc: soc@01c00000 {
  compatible = "simple-bus";
  #address-cells = <2>;
  #size-cells = <2>;
  ranges;
  device_type = "soc";
  dma0:dma-controller@01c02000 {
   compatible = "allwinner,sun50i-dma";
   reg = <0x0 0x01c02000 0x0 0x1000>;
   interrupts = <0 50 4>;
   clocks = <&clk_dma>;
   #dma-cells = <1>;
  };

  mbus0:mbus-controller@01c62000 {
   compatible = "allwinner,sun50i-mbus";
   reg = <0x0 0x01c62000 0x0 0x110>;
   #mbus-cells = <1>;
  };

  arisc {
   compatible = "allwinner,sunxi-arisc";
   #address-cells = <2>;
   #size-cells = <2>;
   clocks = <&clk_losc>, <&clk_iosc>, <&clk_hosc>, <&clk_pll_periph0>;
   clock-names = "losc", "iosc", "hosc", "pll_periph0";
   powchk_used = <0x0>;
   power_reg = <0x02309621>;
   system_power = <50>;
  };

  arisc_space {
   compatible = "allwinner,arisc_space";

   space1 = <0x00040000 0x00000000 0x00014000>;
   space2 = <0x40100000 0x00018000 0x00004000>;
   space3 = <0x40104000 0x00000000 0x00001000>;
   space4 = <0x40105000 0x00000000 0x00001000>;
  };

  standby_space {
   compatible = "allwinner,standby_space";

   space1 = <0x41020000 0x00000000 0x00000800>;
  };

  msgbox: msgbox@1c17000 {
   compatible = "allwinner,msgbox";
   clocks = <&clk_msgbox>;
        clock-names = "clk_msgbox";
       reg = <0x0 0x01c17000 0x0 0x1000>;
       interrupts = <0 49 1>;
       status = "okay";
  };

  hwspinlock: hwspinlock@1c18000 {
   compatible = "allwinner,sunxi-hwspinlock";
   clocks = <&clk_hwspinlock_rst>, <&clk_hwspinlock_bus>;
   clock-names = "clk_hwspinlock_rst" , "clk_hwspinlock_bus";
   reg = <0x0 0x01c18000 0x0 0x1000>;
   status = "okay";
   num-locks = <8>;
  };

  s_cir0: s_cir@1f02000 {
   compatible = "allwinner,s_cir";
   reg = <0x0 0x01f02000 0x0 0x400>;
   interrupts = <0 37 4>;
   pinctrl-names = "default";
   pinctrl-0 = <&s_cir0_pins_a>;
   clocks = <&clk_hosc>,<&clk_cpurcir>;
   supply = "vcc-pl";
   ir_power_key_code = <0>;
   ir_addr_code = <0>;
   status = "okay";
  };

  s_uart0: s_uart@1f02800 {
   compatible = "allwinner,s_uart";
   reg = <0x0 0x01f02800 0x0 0x400>;
   interrupts = <0 38 4>;
   pinctrl-names = "default";
   pinctrl-0 = <&s_uart0_pins_a>;
   status = "okay";
  };

  s_rsb0: s_rsb@1f03400 {
   compatible = "allwinner,s_rsb";
   reg = <0x0 0x01f03400 0x0 0x400>;
   interrupts = <0 39 4>;
   pinctrl-names = "default";
   pinctrl-0 = <&s_rsb0_pins_a>;
   status = "okay";
  };

  s_jtag0: s_jtag0 {
   compatible = "allwinner,s_jtag";
   pinctrl-names = "default";
   pinctrl-0 = <&s_jtag0_pins_a>;
   status = "disable";
  };

  soc_timer0: timer@1c20c00 {
   compatible = "allwinner,sunxi-timer";
   device_type = "timer";
   reg = <0x0 0x01c20c00 0x0 0x90>;
   interrupts = <0 18 1>;
   clock-frequency = <24000000>;
   timer-prescale = <16>;
  };

  rtc: rtc@01f00000 {
   compatible = "allwinner,sun50i-rtc";
   device_type = "rtc";
   reg = <0x0 0x1f00000 0x0 0x218>;
   interrupts = <0 40 4>;
   gpr_offset = <0x100>;
   gpr_len = <4>;
  };

  ve@01c0e000 {
   compatible = "allwinner,sunxi-cedar-ve";
   reg = <0x0 0x01c0e000 0x0 0x1000>,
     <0x0 0x01c00000 0x0 0x10>,
     <0x0 0x01c20000 0x0 0x800>;
   interrupts = <0 58 4>;
   clocks = <&clk_pll_ve>,
       <&clk_ve>;

  };

  uart0: uart@01c28000 {
   compatible = "allwinner,sun50i-uart";
   device_type = "uart0";
   reg = <0x0 0x01c28000 0x0 0x400>;
   interrupts = <0 0 4>;
   clocks = <&clk_uart0>;
   pinctrl-names = "default", "sleep";
   pinctrl-0 = <&uart0_pins_a>;
   pinctrl-1 = <&uart0_pins_b>;
   uart0_port = <0>;
   uart0_type = <2>;
   status = "disabled";
  };

  uart1: uart@01c28400 {
   compatible = "allwinner,sun50i-uart";
   device_type = "uart1";
   reg = <0x0 0x01c28400 0x0 0x400>;
   interrupts = <0 1 4>;
   clocks = <&clk_uart1>;
   pinctrl-names = "default", "sleep";
   pinctrl-0 = <&uart1_pins_a>;
   pinctrl-1 = <&uart1_pins_b>;
   uart1_port = <1>;
   uart1_type = <4>;
   status = "okay";
  };

  uart2: uart@01c28800 {
   compatible = "allwinner,sun50i-uart";
   device_type = "uart2";
   reg = <0x0 0x01c28800 0x0 0x400>;
   interrupts = <0 2 4>;
   clocks = <&clk_uart2>;
   pinctrl-names = "default", "sleep";
   pinctrl-0 = <&uart2_pins_a>;
   pinctrl-1 = <&uart2_pins_b>;
   uart2_port = <2>;
   uart2_type = <4>;
   status = "disabled";
  };

  uart3: uart@01c28c00 {
   compatible = "allwinner,sun50i-uart";
   device_type = "uart3";
   reg = <0x0 0x01c28c00 0x0 0x400>;
   interrupts = <0 3 4>;
   clocks = <&clk_uart3>;
   pinctrl-names = "default", "sleep";
   pinctrl-0 = <&uart3_pins_a>;
   pinctrl-1 = <&uart3_pins_b>;
   uart3_port = <3>;
   uart3_type = <4>;
   status = "disabled";
  };

  uart4: uart@01c29000 {
   compatible = "allwinner,sun50i-uart";
   device_type = "uart4";
   reg = <0x0 0x01c29000 0x0 0x400>;
   interrupts = <0 4 4>;
   clocks = <&clk_uart4>;
   pinctrl-names = "default", "sleep";
   pinctrl-0 = <&uart4_pins_a>;
   pinctrl-1 = <&uart4_pins_b>;
   uart4_port = <4>;
   uart4_type = <4>;
   status = "disabled";
  };

  twi0: twi@0x01c2ac00{
   #address-cells = <1>;
   #size-cells = <0>;
   compatible = "allwinner,sun50i-twi";
   device_type = "twi0";
   reg = <0x0 0x01c2ac00 0x0 0x400>;
   interrupts = <0 6 4>;
   clocks = <&clk_twi0>;
   clock-frequency = <400000>;
   pinctrl-names = "default", "sleep";
   pinctrl-0 = <&twi0_pins_a>;
   pinctrl-1 = <&twi0_pins_b>;
   status = "disabled";
  };

  twi1: twi@0x01c2b000{
   #address-cells = <1>;
   #size-cells = <0>;
   compatible = "allwinner,sun50i-twi";
   device_type = "twi1";
   reg = <0x0 0x01c2b000 0x0 0x400>;
   interrupts = <0 7 4>;
   clocks = <&clk_twi1>;
   clock-frequency = <200000>;
   pinctrl-names = "default", "sleep";
   pinctrl-0 = <&twi1_pins_a>;
   pinctrl-1 = <&twi1_pins_b>;
   status = "disabled";
  };

  twi2: twi@0x01c2b400{
   #address-cells = <1>;
   #size-cells = <0>;
   compatible = "allwinner,sun50i-twi";
   device_type = "twi2";
   reg = <0x0 0x01c2b400 0x0 0x400>;
   interrupts = <0 8 4>;
   clocks = <&clk_twi2>;
   clock-frequency = <200000>;
   pinctrl-names = "default", "sleep";
   pinctrl-0 = <&twi2_pins_a>;
   pinctrl-1 = <&twi2_pins_b>;
   status = "disabled";
  };

  usbc0:usbc0@0 {
   device_type = "usbc0";
   compatible = "allwinner,sunxi-otg-manager";
   usb_port_type = <2>;
   usb_detect_type = <1>;
   usb_id_gpio = <&pio 7 9 0 1 1 1>;
   usb_det_vbus_gpio = "axp_ctrl";
   usb_drv_vbus_gpio = <&axp_pio 15 3 1 1 1 1>;
   usb_host_init_state = <0>;
   usb_regulator_io = "nocare";
   usb_wakeup_suspend = <0>;
   usb_luns = <3>;
   usb_serial_unique = <0>;
   usb_serial_number = "20080411";
   rndis_wceis = <1>;
   status = "okay";
  };

  udc:udc-controller@0x01c19000 {
   compatible = "allwinner,sunxi-udc";
   reg = <0x0 0x01c19000 0x0 0x1000>,
                         <0x0 0x01c00000 0x0 0x100>;
   interrupts = <0 71 4>;
   clocks = <&clk_usbphy0>, <&clk_usbotg>;
   status = "okay";
  };

  ehci0:ehci0-controller@0x01c1a000 {
   compatible = "allwinner,sunxi-ehci0";
   reg = <0x0 0x01c1a000 0x0 0xFFF>,
                         <0x0 0x01c00000 0x0 0x100>,
                         <0x0 0x01c19000 0x0 0x1000>;
   interrupts = <0 72 4>;
   clocks = <&clk_usbphy0>, <&clk_usbehci0>;
   hci_ctrl_no = <0>;
   status = "okay";
  };

  ohci0:ohci0-controller@0x01c1a400 {
   compatible = "allwinner,sunxi-ohci0";
   reg = <0x0 0x01c1a000 0x0 0xFFF>,
                         <0x0 0x01c00000 0x0 0x100>,
                         <0x0 0x01c19000 0x0 0x1000>;
   interrupts = <0 73 4>;
   clocks = <&clk_usbphy0>, <&clk_usbohci0>;
   hci_ctrl_no = <0>;
   status = "okay";
  };

  usbc1:usbc1@0 {
   device_type = "usbc1";
   usb_drv_vbus_gpio = <&pio 1 6 1 1 1 1>;
   usb_host_init_state = <1>;
   usb_regulator_io = "nocare";
   usb_wakeup_suspend = <0>;

   usb_hsic_used = <0>;
   usb_hsic_regulator_io = "vcc-hsic-12";

   usb_hsic_ctrl = <0>;
   usb_hsic_rdy_gpio;

   usb_hsic_usb3503_flag = <0>;
   usb_hsic_hub_connect_gpio;
   usb_hsic_int_n_gpio;
   usb_hsic_reset_n_gpio;
   status = "okay";
  };

  ehci1:ehci1-controller@0x01c1b000 {
   compatible = "allwinner,sunxi-ehci1";
   reg = <0x0 0x01c1b000 0x0 0xFFF>,
                         <0x0 0x01c00000 0x0 0x100>,
                         <0x0 0x01c19000 0x0 0x1000>;
   interrupts = <0 74 4>;
   clocks = <&clk_usbphy1>, <&clk_usbehci1>, <&clk_usbhsic>, <&clk_usbhsic12m>, <&clk_pll_hsic>;
   hci_ctrl_no = <1>;
   status = "okay";
  };

  ohci1:ohci1-controller@0x01c1b400 {
   compatible = "allwinner,sunxi-ohci1";
   reg = <0x0 0x01c1b000 0x0 0xFFF>,
                         <0x0 0x01c00000 0x0 0x100>,
                         <0x0 0x01c19000 0x0 0x1000>;
   interrupts = <0 75 4>;
   clocks = <&clk_usbphy1>, <&clk_usbohci1>;
   hci_ctrl_no = <1>;
   status = "okay";
  };
  codec:codec@0x01c22c00 {
   compatible = "allwinner,sunxi-internal-codec";
   reg = <0x0 0x01c22c00 0x0 0x478>,
         <0x0 0x01f015c0 0x0 0x0>;
   clocks = <&clk_pll_audiox4>;

   pinctrl-names = "aif2-default","aif3-default","aif2-sleep","aif3-sleep";
   pinctrl-0 = <&aif2_pins_a>;
   pinctrl-1 = <&aif3_pins_a>;
   pinctrl-2 = <&aif2_pins_b>;
   pinctrl-3 = <&aif3_pins_b>;


   gpio-spk = <&pio 7 7 1 1 1 1>;

   headphonevol = <0x3b>;
   spkervol = <0x1b>;
   earpiecevol = <0x1e>;
   maingain = <0x4>;
   headsetmicgain = <0x4>;
   adcagc_cfg = <0x0>;
   adcdrc_cfg = <0x0>;
   adchpf_cfg = <0x0>;
   dacdrc_cfg = <0x0>;
   dachpf_cfg = <0x0>;
    aif1_lrlk_div = <0x40>;
    aif2_lrlk_div = <0x40>;
   aif2config = <0x0>;
   aif3config = <0x0>;
   pa_sleep_time = <0x15e>;
   dac_digital_vol = <0xa0a0>;
   status = "okay";
  };

  i2s:i2s0-controller@0x01c22c00 {
   compatible = "allwinner,sunxi-internal-i2s";
   reg = <0x0 0x01c22c00 0x0 0x478>;
   clocks = <&clk_pll_audio>,<&clk_adda>;
   status = "okay";
  };

  daudio0:daudio@0x01c22000 {
   compatible = "allwinner,sunxi-daudio";
   reg = <0x0 0x01c22000 0x0 0x58>;
   clocks = <&clk_pll_audio>,<&clk_i2s0>;
   pinctrl-names = "default","sleep";
   pinctrl-0 = <&daudio0_pins_a>;
   pinctrl-1 = <&daudio0_pins_b>;
   pcm_lrck_period = <0x20>;
   pcm_lrckr_period = <0x01>;
   slot_width_select = <0x20>;
   pcm_lsb_first = <0x0>;
   tx_data_mode = <0x0>;
   rx_data_mode = <0x0>;
   daudio_master = <0x04>;
   audio_format = <0x01>;
   signal_inversion = <0x01>;
   frametype = <0x0>;
   tdm_config = <0x01>;
   tdm_num = <0x0>;
   status = "okay";
  };
  daudio1:daudio@0x01c22400 {
   compatible = "allwinner,sunxi-daudio";
   reg = <0x0 0x01c22400 0x0 0x58>;
   pinctrl-names = "default","sleep";
   pinctrl-0 = <&daudio1_pins_a>;
   pinctrl-1 = <&daudio1_pins_b>;
   clocks = <&clk_pll_audio>,<&clk_i2s1>;
   pcm_lrck_period = <0x20>;
   pcm_lrckr_period = <0x01>;
   slot_width_select = <0x20>;
   pcm_lsb_first = <0x0>;
   tx_data_mode = <0x0>;
   rx_data_mode = <0x0>;
   daudio_master = <0x04>;
   audio_format = <0x01>;
   signal_inversion = <0x01>;
   frametype = <0x0>;
   tdm_config = <0x01>;
   tdm_num = <0x1>;
   status = "okay";
  };
  daudio2:daudio@0x01c22800{
   compatible = "allwinner,sunxi-tdmhdmi";
   reg = <0x0 0x01c22800 0x0 0x58>;
   clocks = <&clk_pll_audio>,<&clk_i2s2>;
   status = "okay";
  };
  spdif:spdif-controller@0x01c21000{
   compatible = "allwinner,sunxi-spdif";
   reg = <0x0 0x01c21000 0x0 0x38>;
   clocks = <&clk_pll_audio>,<&clk_spdif>;
   pinctrl-names = "default","sleep";
   pinctrl-0 = <&spdif_pins_a>;
   pinctrl-1 = <&spdif_pins_b>;
   status = "okay";
  };
  sndcodec:sound@0 {
   compatible = "allwinner,sunxi-codec-machine";
   interrupts = <0 28 4>;
   sunxi,i2s-controller = <&i2s>;
   sunxi,audio-codec = <&codec>;
   aif2fmt = <3>;
   aif3fmt = <3>;
   aif2master = <1>;
   hp_detect_case = <0x00>;
   status = "okay";
  };

  snddaudio0:sound@1{
   compatible = "allwinner,sunxi-daudio0-machine";
   sunxi,daudio0-controller = <&daudio0>;
   status = "okay";
  };
  snddaudio1:sound@2{
   compatible = "allwinner,sunxi-daudio1-machine";
   sunxi,daudio1-controller = <&daudio1>;
   status = "okay";
  };
  sndhdmi:sound@3{
   compatible = "allwinner,sunxi-hdmi-machine";
   sunxi,hdmi-controller = <&daudio2>;
   status = "okay";
  };

  sndspdif:sound@4{
   compatible = "allwinner,sunxi-spdif-machine";
   sunxi,spdif-controller = <&spdif>;
   status = "okay";
  };

  spi0: spi@01c68000 {
   #address-cells = <1>;
   #size-cells = <0>;
   compatible = "allwinner,sun50i-spi";
   device_type = "spi0";
   reg = <0x0 0x01c68000 0x0 0x1000>;
   interrupts = <0 65 4>;
   clocks = <&clk_pll_periph0>, <&clk_spi0>;
   clock-frequency = <100000000>;
   pinctrl-names = "default", "sleep";
   pinctrl-0 = <&spi0_pins_a &spi0_pins_b>;
   pinctrl-1 = <&spi0_pins_c>;
   spi0_cs_number = <1>;
   spi0_cs_bitmap = <1>;
   status = "disabled";
  };

  spi1: spi@01c69000 {
   #address-cells = <1>;
   #size-cells = <0>;
   compatible = "allwinner,sun50i-spi";
   device_type = "spi1";
   reg = <0x0 0x01c69000 0x0 0x1000>;
   interrupts = <0 66 4>;
   clocks = <&clk_pll_periph0>, <&clk_spi1>;
   clock-frequency = <100000000>;
   pinctrl-names = "default", "sleep";
   pinctrl-0 = <&spi1_pins_a &spi1_pins_b>;
   pinctrl-1 = <&spi1_pins_c>;
   spi1_cs_number = <1>;
   spi1_cs_bitmap = <1>;
   status = "disabled";
  };

  sdc2: sdmmc@01C11000 {
   compatible = "allwinner,sun50i-sdmmc2";
   device_type = "sdc2";
   reg = <0x0 0x01C11000 0x0 0x1000>;
   interrupts = <0 62 0x0104>;
   clocks = <&clk_hosc>,<&clk_pll_periph1x2>,<&clk_sdmmc2_mod>,<&clk_sdmmc2_bus>,<&clk_sdmmc2_rst>;
     clock-names = "osc24m","pll_periph","mmc","ahb","rst";
      pinctrl-names = "default","sleep";
   pinctrl-0 = <&sdc2_pins_a>;
   pinctrl-1 = <&sdc2_pins_b>;
    bus-width = <8>;





       max-frequency = <50000000>;
# 855 "arch/arm64/boot/dts/sun50iw1p1.dtsi"
       sdc_tm4_sm0_freq0 = <0>;
       sdc_tm4_sm0_freq1 = <0>;
       sdc_tm4_sm1_freq0 = <0x00000000>;
       sdc_tm4_sm1_freq1 = <0>;
       sdc_tm4_sm2_freq0 = <0x00000000>;
       sdc_tm4_sm2_freq1 = <0>;
       sdc_tm4_sm3_freq0 = <0x05000000>;
       sdc_tm4_sm3_freq1 = <0x00000005>;
       sdc_tm4_sm4_freq0 = <0x00050000>;
       sdc_tm4_sm4_freq1 = <0x00000004>;
# 874 "arch/arm64/boot/dts/sun50iw1p1.dtsi"
   status = "okay";

       };

  sdc0: sdmmc@01c0f000 {
   compatible = "allwinner,sun50i-sdmmc0";
   device_type = "sdc0";
   reg = <0x0 0x01c0f000 0x0 0x1000>;
   interrupts = <0 60 0x0104>;
   clocks = <&clk_hosc>,<&clk_pll_periph1x2>,<&clk_sdmmc0_mod>,<&clk_sdmmc0_bus>,<&clk_sdmmc0_rst>;
   clock-names = "osc24m","pll_periph","mmc","ahb","rst";
   pinctrl-names = "default","sleep";
   pinctrl-0 = <&sdc0_pins_a>;
   pinctrl-1 = <&sdc0_pins_b>;
   max-frequency = <50000000>;
   bus-width = <4>;
   broken-cd;

   cd-gpios = <&pio 5 6 0 1 2 0>;
# 915 "arch/arm64/boot/dts/sun50iw1p1.dtsi"
   status = "okay";

  };


  sdc1: sdmmc@1C10000 {
   compatible = "allwinner,sun50i-sdmmc1";
   device_type = "sdc1";
   reg = <0x0 0x1C10000 0x0 0x1000>;
   interrupts = <0 61 0x0104>;
   clocks = <&clk_hosc>,<&clk_pll_periph1x2>,<&clk_sdmmc1_mod>,<&clk_sdmmc1_bus>,<&clk_sdmmc1_rst>;
   clock-names = "osc24m","pll_periph","mmc","ahb","rst";
   pinctrl-names = "default","sleep";
   pinctrl-0 = <&sdc1_pins_a>;
   pinctrl-1 = <&sdc1_pins_b>;
   max-frequency = <50000000>;
   bus-width = <4>;
# 951 "arch/arm64/boot/dts/sun50iw1p1.dtsi"
      sunxi-dly-52M-ddr4 = <1 0 0 0 2>;

      sunxi-dly-104M = <1 0 0 0 1>;

      sunxi-dly-208M = <1 0 0 0 1>;




   status = "okay";

  };


  disp: disp@01000000 {
   compatible = "allwinner,sun50i-disp";
   reg = <0x0 0x01000000 0x0 0x00300000>,
    <0x0 0x01c0c000 0x0 0x17fc>,
    <0x0 0x01ca0000 0x0 0x10fc>;
   interrupts = <0 86 0x0104>, <0 87 0x0104>,
    <0 89 0x0104>;
   clocks = <&clk_de>,<&clk_tcon0>,
    <&clk_lvds>,<&clk_mipidsi>,<&clk_tcon1>;

   status = "okay";
  };

  lcd0: lcd0@01c0c000 {
   compatible = "allwinner,sunxi-lcd0";
   pinctrl-names = "active","sleep";

   status = "okay";
  };

  hdmi: hdmi@01ee0000 {
   compatible = "allwinner,sunxi-hdmi";
   reg = <0x0 0x01ee0000 0x0 0x20000>;
   clocks = <&clk_hdmi>,<&clk_hdmi_slow>;
  };

  soc_tr: tr@01000000 {
   compatible = "allwinner,sun50i-tr";
   reg = <0x0 0x01000000 0x0 0x000200bc>;
   interrupts = <0 96 0x0104>;
   clocks = <&clk_de>;
   status = "okay";
  };

  pwm: pwm@01c21400 {
   compatible = "allwinner,sunxi-pwm";
   reg = <0x0 0x01c21400 0x0 0x3c>;
   pwm-number = <1>;
   pwm-base = <0x0>;
   pwms = <&pwm0>;
  };

  pwm0: pwm0@01c21400 {
   compatible = "allwinner,sunxi-pwm0";
   pinctrl-names = "active", "sleep";
   reg_base = <0x01c21400>;
   reg_busy_offset = <0x00>;
   reg_busy_shift = <28>;
   reg_enable_offset = <0x00>;
   reg_enable_shift = <4>;
   reg_clk_gating_offset = <0x00>;
   reg_clk_gating_shift = <6>;
   reg_bypass_offset = <0x00>;
   reg_bypass_shift = <9>;
   reg_pulse_start_offset = <0x00>;
   reg_pulse_start_shift = <8>;
   reg_mode_offset = <0x00>;
   reg_mode_shift = <7>;
   reg_polarity_offset = <0x00>;
   reg_polarity_shift = <5>;
   reg_period_offset = <0x04>;
   reg_period_shift = <16>;
   reg_period_width = <16>;
   reg_active_offset = <0x04>;
   reg_active_shift = <0>;
   reg_active_width = <16>;
   reg_prescal_offset = <0x00>;
   reg_prescal_shift = <0>;
   reg_prescal_width = <4>;
  };

  s_pwm: s_pwm@1f03800 {
   compatible = "allwinner,sunxi-s_pwm";
   reg = <0x0 0x01f03800 0x0 0x3c>;
   pwm-number = <1>;
   pwm-base = <0x10>;
   pwms = <&spwm0>;
  };

  spwm0: spwm0@0x01f03800 {
   compatible = "allwinner,sunxi-pwm16";
   pinctrl-names = "active", "sleep";
   reg_base = <0x01f03800>;
   reg_busy_offset = <0x00>;
   reg_busy_shift = <28>;
   reg_enable_offset = <0x00>;
   reg_enable_shift = <4>;
   reg_clk_gating_offset = <0x00>;
   reg_clk_gating_shift = <6>;
   reg_bypass_offset = <0x00>;
   reg_bypass_shift = <9>;
   reg_pulse_start_offset = <0x00>;
   reg_pulse_start_shift = <8>;
   reg_mode_offset = <0x00>;
   reg_mode_shift = <7>;
   reg_polarity_offset = <0x00>;
   reg_polarity_shift = <5>;
   reg_period_offset = <0x04>;
   reg_period_shift = <16>;
   reg_period_width = <16>;
   reg_active_offset = <0x04>;
   reg_active_shift = <0>;
   reg_active_width = <16>;
   reg_prescal_offset = <0x00>;
   reg_prescal_shift = <0>;
   reg_prescal_width = <4>;
  };

  boot_disp: boot_disp {
   compatible = "allwinner,boot_disp";
  };

  csi_cci0:cci@0x01cb3000 {
   compatible = "allwinner,sunxi-csi_cci";
   reg = <0x0 0x01cb3000 0x0 0x1000>;
   interrupts = <0 85 4>;
   status = "okay";
  };
  csi_res0:csi_res@0x01cb0000 {
   compatible = "allwinner,sunxi-csi";
   reg = <0x0 0x01cb0000 0x0 0x1000>;
   status = "okay";
  };
  csi0:vfe@0 {
   device_type= "csi0";
   compatible = "allwinner,sunxi-vfe";
   interrupts = <0 84 4>;
   clocks = <&clk_csi_s>, <&clk_csi_m>,<&clk_csi_misc>,
         <&clk_pll_periph0>,<&clk_hosc>,<&clk_pll_periph1>;
   pinctrl-names = "default","sleep";
   pinctrl-0 = <&csi0_pins_a>;
   pinctrl-1 = <&csi0_pins_b>;
   csi0_sensor_list = <0>;
   csi0_mck = <&pio 4 1 1 0 1 0>;
   status = "okay";
   csi0_dev0:dev@0{
    csi0_dev0_mname = "ov5640";
    csi0_dev0_twi_addr = <0x78>;
    csi0_dev0_pos = "rear";
    csi0_dev0_isp_used = <1>;
    csi0_dev0_fmt = <0>;
    csi0_dev0_stby_mode = <0>;
    csi0_dev0_vflip = <0>;
    csi0_dev0_hflip = <0>;
    csi0_dev0_iovdd = "iovdd-csi";
    csi0_dev0_iovdd_vol = <2800000>;
    csi0_dev0_avdd = "avdd-csi";
    csi0_dev0_avdd_vol = <2800000>;
    csi0_dev0_dvdd = "dvdd-csi-18";
    csi0_dev0_dvdd_vol = <1500000>;
    csi0_dev0_afvdd = "";
    csi0_dev0_afvdd_vol = <>;
    csi0_dev0_power_en = <>;
    csi0_dev0_reset = <&pio 4 14 1 0 1 0>;
    csi0_dev0_pwdn = <&pio 4 15 1 0 1 0>;
    csi0_dev0_flash_used = <1>;
    csi0_dev0_flash_type = <2>;
    csi0_dev0_flash_en = <>;
    csi0_dev0_flash_mode = <>;
    csi0_dev0_flvdd = "vdd-csi-led";
    csi0_dev0_flvdd_vol = <3300000>;
    csi0_dev0_af_pwdn = <>;
    csi0_dev0_act_used = <0>;
    csi0_dev0_act_name = "ad5820_act";
    csi0_dev0_act_slave = <0x18>;
    status = "okay";
   };
   csi0_dev1:dev@1{
    csi0_dev1_mname = "";
    csi0_dev1_twi_addr = <0x78>;
    csi0_dev1_pos = "rear";
    csi0_dev1_isp_used = <1>;
    csi0_dev1_fmt = <0>;
    csi0_dev1_stby_mode = <0>;
    csi0_dev1_vflip = <0>;
    csi0_dev1_hflip = <0>;
    csi0_dev1_iovdd = "iovdd-csi";
    csi0_dev1_iovdd_vol = <2800000>;
    csi0_dev1_avdd = "avdd-csi";
    csi0_dev1_avdd_vol = <2800000>;
    csi0_dev1_dvdd = "dvdd-csi-18";
    csi0_dev1_dvdd_vol = <1500000>;
    csi0_dev1_afvdd = "";
    csi0_dev1_afvdd_vol = <>;
    csi0_dev1_power_en = <>;
    csi0_dev1_reset = <>;
    csi0_dev1_pwdn = <>;
    csi0_dev1_flash_used = <1>;
    csi0_dev1_flash_type = <2>;
    csi0_dev1_flash_en = <>;
    csi0_dev1_flash_mode = <>;
    csi0_dev1_flvdd = "vdd-csi-led";
    csi0_dev1_flvdd_vol = <3300000>;
    csi0_dev1_af_pwdn = <>;
    csi0_dev1_act_used = <0>;
    csi0_dev1_act_name = "ad5820_act";
    csi0_dev1_act_slave = <0x18>;
    status = "disabled";
   };
  };
  Vdevice: vdevice@0{
   compatible = "allwinner,sun50i-vdevice";
   pinctrl-names = "default";
   pinctrl-0 = <&vdevice_pins_a>;
   test-gpios = <&r_pio 11 0 1 2 3 4>;
   status = "okay";
  };
  cryptoengine: ce@1c15000 {
   compatible = "allwinner,sunxi-ce";
   reg = <0x0 0x01c15000 0x0 0x80>,
      <0x0 0x01c15800 0x0 0x80>;
   interrupts = <0 94 0xff01>,
       <0 80 0xff01>;
   clock-frequency = <300000000>,
         <200000000>;
   clocks = <&clk_ce>, <&clk_pll_periph0x2>;
  };
  di:deinterlace@0x01e00000{
   #address-cells = <1>;
   #size-cells = <0>;
   compatible = "allwinner,sunxi-deinterlace";
   reg = <0x0 0x01e00000 0x0 0x77c>;
   interrupts = <0 93 4>;
   clocks = <&clk_deinterlace> ,<&clk_pll_periph0>;
   status = "okay";
  };
  smc:smartcard@0x01c2c400{
   #address-cells = <1>;
   #size-cells = <0>;
   compatible = "allwinner,sunxi-scr";
   reg = <0x0 0x01c2c400 0x0 0x100>;
   interrupts = <0 83 4>;
   clocks = <&clk_scr>, <&clk_apb2>;
   clock-frequency = <24000000>;
   pinctrl-names = "default";
   pinctrl-0 = <&scr_pins_a>;
   status = "okay";
  };
  nmi:nmi@0x01f00c00{
   #address-cells = <1>;
   #size-cells = <0>;
   compatible = "allwinner,sunxi-nmi";
   reg = <0x0 0x01f00c00 0x0 0x50>;
   nmi_irq_ctrl = <0x0c>;
   nmi_irq_en = <0x40>;
   nmi_irq_status = <0x10>;
   nmi_irq_mask = <0x50>;
   status = "okay";
  };
  pmu0:pmu0@0{
   compatible = "allwinner,pmu0";
   device_type = "pmu0";
   pmu_batdeten = <1>;
   pmu_init_chgend_rate = <20>;
   pmu_init_chg_enabled = <1>;
   pmu_init_adc_freq = <800>;
   pmu_init_adcts_freq = <800>;
   pmu_init_chg_pretime = <70>;
   pmu_init_chg_csttime = <720>;
   pmu_batt_cap_correct = <1>;
   pmu_chg_end_on_en = <0>;

   pmu_pwroff_vol = <3300>;
   pmu_pwron_vol = <2600>;
   pmu_powkey_off_delay_time = <0>;
   pmu_pwrok_time = <64>;
   pmu_reset_shutdown_en = <1>;
   pmu_restvol_adjust_time = <60>;
   pmu_ocv_cou_adjust_time = <60>;
   pmu_vbusen_func = <1>;
   pmu_reset = <0>;
   pmu_IRQ_wakeup = <0>;
   pmu_hot_shutdowm = <1>;
   pmu_inshort = <0>;
   pmu_bat_shutdown_ltf = <3200>;
   pmu_bat_shutdown_htf = <237>;
   status = "okay";
  };
  pmu0_regu:regu@0{
   compatible = "allwinner,pmu0_regu";
   regulator_count = <23>;
   status = "okay";
  };

  nand0:nand0@01c03000 {
   compatible = "allwinner,sun50i-nand";
   device_type = "nand0";
   reg = <0x0 0x01c03000 0x0 0x1000>;
   interrupts = <0 70 0x04>;
   clocks = <&clk_pll_periph0>,<&clk_nand>;
   pinctrl-names = "default", "sleep";
   pinctrl-0 = <&nand0_pins_a &nand0_pins_b>;
   pinctrl-1 = <&nand0_pins_c>;
   nand0_regulator1 = "vcc-nand";
   nand0_regulator2 = "none";
   nand0_cache_level = <0x55aaaa55>;
   nand0_flush_cache_num = <0x55aaaa55>;
   nand0_capacity_level = <0x55aaaa55>;
   nand0_id_number_ctl = <0x55aaaa55>;
   nand0_print_level = <0x55aaaa55>;
   nand0_p0 = <0x55aaaa55>;
   nand0_p1 = <0x55aaaa55>;
   nand0_p2 = <0x55aaaa55>;
   nand0_p3 = <0x55aaaa55>;
   status = "okay";
  };

  sunxi_thermal_sensor:thermal_sensor{
   compatible = "allwinner,thermal_sensor";
   reg = <0x0 0x01c25000 0x0 0x400>;
   interrupts = <0 31 0>;
   clocks = <&clk_hosc>,<&clk_ths>;
   sensor_num = <3>;
   shut_temp= <120>;
   status = "okay";

   combine0:combine0{
    #thermal-sensor-cells = <1>;
    combine_cnt = <3>;
    combine_type = "max";
    combine_chn = <0 1 2>;
   };
  };

  cpu_budget_cooling:cpu_budget_cool{
   compatible = "allwinner,budget_cooling";
   #cooling-cells = <2>;
   status = "okay";
   state_cnt = <10>;
   cluster_num = <1>;
   state0 = <1152000 4>;
   state1 = <1104000 4>;
   state2 = <1056000 4>;
   state3 = <1008000 4>;
   state4 = <960000 4>;
   state5 = <912000 4>;
   state6 = <816000 4>;
   state7 = <648000 4>;
   state8 = <648000 2>;
   state9 = <648000 1>;
  };

  gpu_cooling:gpu_cooling{
   compatible = "allwinner,gpu_cooling";
   reg = <0x0 0x0 0x0 0x0>;
   #cooling-cells = <2>;
   status = "okay";
   state_cnt = <3>;
   state0 = <0>;
   state1 = <360>;
   state2 = <144>;
  };

  thermal-zones{
   soc_thermal{

    polling-delay-passive = <500>;
    polling-delay = <2000>;
    thermal-sensors = <&combine0 0>;

    trips{
     cpu_trip0:t0{
      temperature = <80>;
      type = "passive";
      hysteresis = <0>;
     };
     cpu_trip1:t1{
      temperature = <85>;
      type = "passive";
      hysteresis = <0>;
     };
     cpu_trip2:t2{
      temperature = <90>;
      type = "passive";
      hysteresis = <0>;
     };
     cpu_trip3:t3{
      temperature = <95>;
      type = "passive";
      hysteresis = <0>;
     };
     gpu_trip0:t4{
      temperature = <85>;
      type = "passive";
      hysteresis = <0>;
     };
     gpu_trip1:t5{
      temperature = <95>;
      type = "passive";
      hysteresis = <0>;
     };
     crt_trip:t6{
      temperature = <110>;
      type = "critical";
      hysteresis = <0>;
     };
    };

    cooling-maps{
     bind0{
      contribution = <0>;
      trip = <&cpu_trip0>;
      cooling-device = <&cpu_budget_cooling 1 1>;
     };
     bind1{
      contribution = <0>;
      trip = <&cpu_trip1>;
      cooling-device = <&cpu_budget_cooling 2 2>;
     };
     bind2{
      contribution = <0>;
      trip = <&cpu_trip2>;
      cooling-device = <&cpu_budget_cooling 3 6>;
     };
     bind3{
      contribution = <0>;
      trip = <&cpu_trip3>;
      cooling-device = <&cpu_budget_cooling 7 9>;
     };
     bind4{
      contribution = <0>;
      trip = <&gpu_trip0>;
      cooling-device = <&gpu_cooling 1 1>;
     };
     bind5{
      contribution = <0>;
      trip = <&gpu_trip1>;
      cooling-device = <&gpu_cooling 2 2>;
     };
    };
   };
  };

  keyboard0:keyboard{
   compatible = "allwinner,keyboard_2000mv";
   reg = <0x0 0x01c21800 0x0 0x400>;
   interrupts = <0 30 0>;
   status = "okay";
   key_cnt = <5>;
   key1 = <240 115>;
   key2 = <500 114>;
   key3 = <700 139>;
   key4 = <890 28>;
   key5 = <2000 102>;
  };

  gmac0: eth@01c30000 {
   compatible = "allwinner,sunxi-gmac";
   reg = <0x0 0x01c30000 0x0 0x40000>,
       <0x0 0x01c00000 0x0 0x30>;
   pinctrl-names = "default";
   pinctrl-0 = <&gmac_pins_a>;
   interrupts = <0 82 4>;
   interrupt-names = "gmacirq";
   clocks = <&clk_gmac>;
   clock-names = "gmac";
   phy-mode = "rgmii";
   tx-delay = <7>;
   rx-delay = <31>;
   gmac_power1 = "axp81x_dldo2:2500000";
   gmac_power2 = "axp81x_eldo2:1800000";
   gmac_power3 = "axp81x_fldo1:1200000";
   status = "disable";
  };
 };
};
# 9 "arch/arm64/boot/dts/sun50iw1p1-fpga.dts" 2

/{

 soc@01c00000 {
  uart0: uart@01c28000 {
   status = "okay";
  };

  twi0: twi@0x01c2ac00{
   status = "disabled";

   eeprom@50 {
    compatible = "atmel,24c16";
    reg = <0x50>;
   };
  };

  spi0: spi@01c68000 {
   status = "disabled";

   nor_flash@0 {
    #address-cells = <1>;
    #size-cells = <1>;
    compatible = "atmel,at25df641";
    spi-max-frequency = <50000000>;
    reg = <0>;

    partition@0 {
     label = "NorFlash part0";
     reg = <0x00000000 0x00800000>;
    };
   };
  };
 };
};
